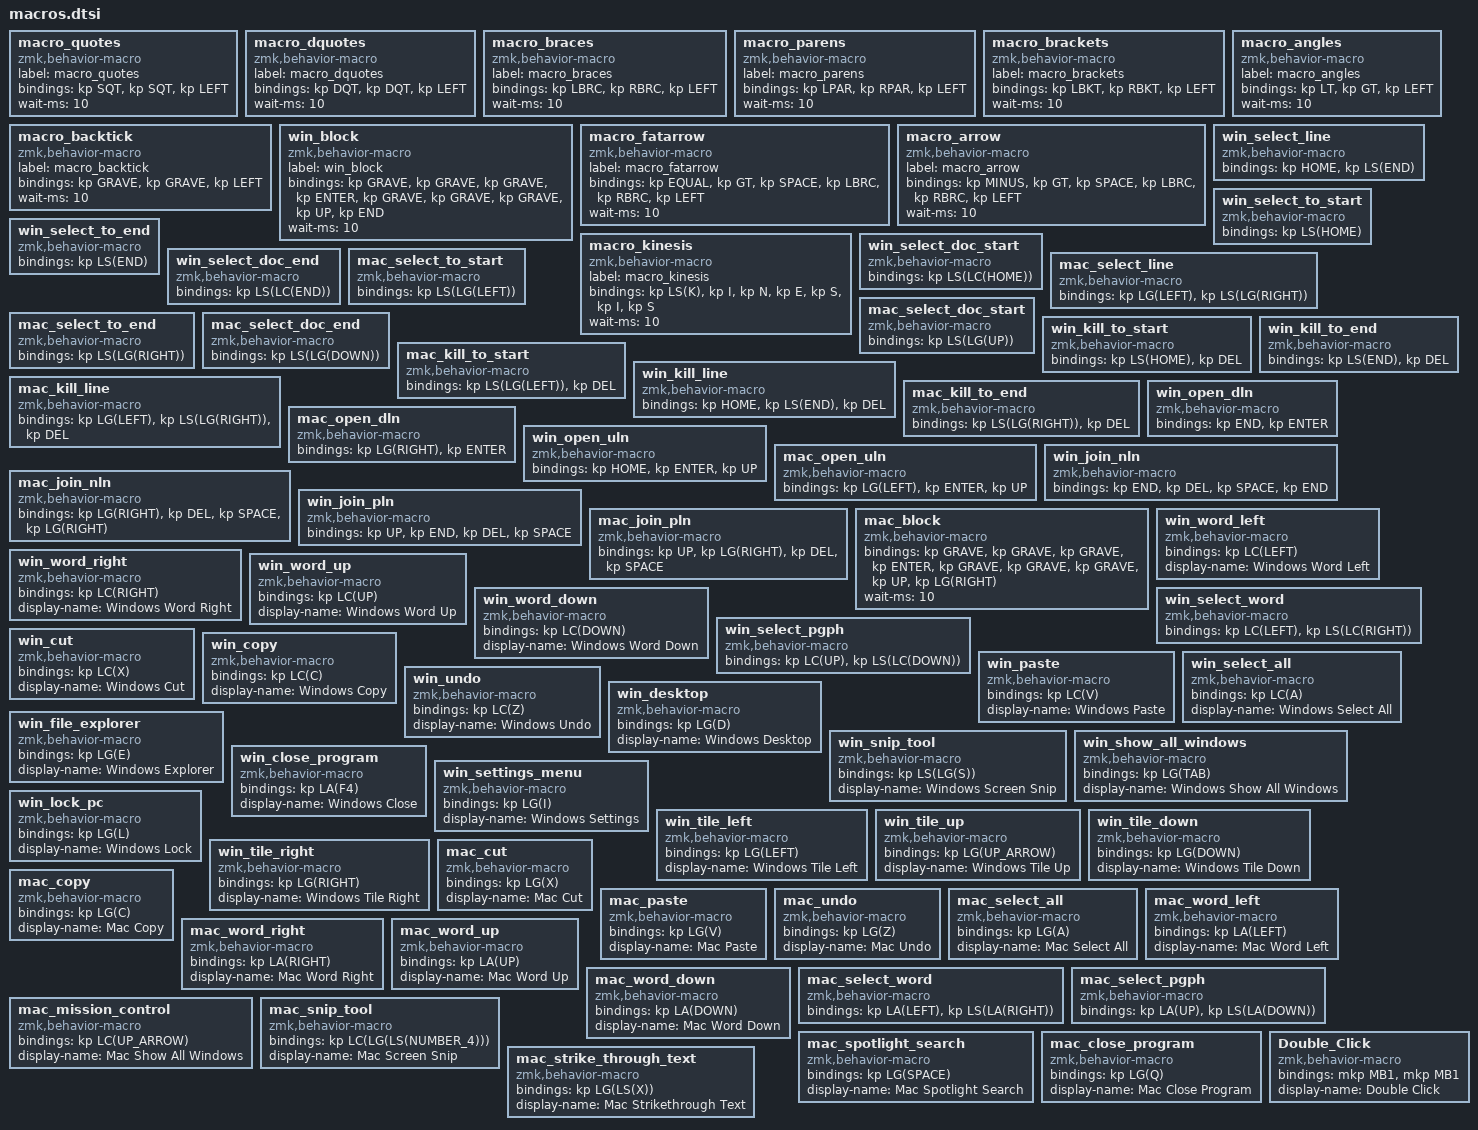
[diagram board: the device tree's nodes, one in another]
macro_quotes: macro_quotes {
    compatible = "zmk,behavior-macro";
    label = "macro_quotes";
    #binding-cells = <0>;
    bindings = <&kp SQT>, <&kp SQT>, <&kp LEFT>;
    wait-ms = <10>;
};
macro_dquotes: macro_dquotes {
    compatible = "zmk,behavior-macro";
    label = "macro_dquotes";
    #binding-cells = <0>;
    bindings = <&kp DQT>, <&kp DQT>, <&kp LEFT>;
    wait-ms = <10>;
};
macro_braces: macro_braces {
    compatible = "zmk,behavior-macro";
    label = "macro_braces";
    #binding-cells = <0>;
    bindings = <&kp LBRC>, <&kp RBRC>, <&kp LEFT>;
    wait-ms = <10>;
};
macro_parens: macro_parens {
    compatible = "zmk,behavior-macro";
    label = "macro_parens";
    #binding-cells = <0>;
    bindings = <&kp LPAR>, <&kp RPAR>, <&kp LEFT>;
    wait-ms = <10>;
};
macro_brackets: macro_brackets {
    compatible = "zmk,behavior-macro";
    label = "macro_brackets";
    #binding-cells = <0>;
    bindings = <&kp LBKT>, <&kp RBKT>, <&kp LEFT>;
    wait-ms = <10>;
};
macro_angles: macro_angles {
    compatible = "zmk,behavior-macro";
    label = "macro_angles";
    #binding-cells = <0>;
    bindings = <&kp LT>, <&kp GT>, <&kp LEFT>;
    wait-ms = <10>;
};
macro_backtick: macro_backtick {
    compatible = "zmk,behavior-macro";
    label = "macro_backtick";
    #binding-cells = <0>;
    bindings = <&kp GRAVE>, <&kp GRAVE>, <&kp LEFT>;
    wait-ms = <10>;
};
win_block: win_block {
    compatible = "zmk,behavior-macro";
    label = "win_block";
    #binding-cells = <0>;
    bindings = <&kp GRAVE>, <&kp GRAVE>, <&kp GRAVE>, <&kp ENTER>, <&kp GRAVE>, <&kp GRAVE>, <&kp GRAVE>, <&kp UP>, <&kp END>;
    wait-ms = <10>;
};
macro_fatarrow: macro_fatarrow {
    compatible = "zmk,behavior-macro";
    label = "macro_fatarrow";
    #binding-cells = <0>;
    bindings = <&kp EQUAL>, <&kp GT>, <&kp SPACE>, <&kp LBRC>, <&kp RBRC>, <&kp LEFT>;
    wait-ms = <10>;
};
macro_arrow: macro_arrow {
    compatible = "zmk,behavior-macro";
    label = "macro_arrow";
    #binding-cells = <0>;
    bindings = <&kp MINUS>, <&kp GT>, <&kp SPACE>, <&kp LBRC>, <&kp RBRC>, <&kp LEFT>;
    wait-ms = <10>;
};
macro_kinesis: macro_kinesis {
    compatible = "zmk,behavior-macro";
    label = "macro_kinesis";
    #binding-cells = <0>;
    bindings = <&kp LS(K)>, <&kp I>, <&kp N>, <&kp E>, <&kp S>, <&kp I>, <&kp S>;
    wait-ms = <10>;
};
win_select_line: win_select_line {
    compatible = "zmk,behavior-macro";
    #binding-cells = <0>;
    bindings = <
        &kp HOME
        &kp LS(END)
    >;
};
win_select_to_start: win_select_to_start {
    compatible = "zmk,behavior-macro";
    #binding-cells = <0>;
    bindings = <
        &kp LS(HOME)
    >;
};
win_select_to_end: win_select_to_end {
    compatible = "zmk,behavior-macro";
    #binding-cells = <0>;
    bindings = <
        &kp LS(END)
    >;
};
win_select_doc_start: win_select_doc_start {
    compatible = "zmk,behavior-macro";
    #binding-cells = <0>;
    bindings = <
        &kp LS(LC(HOME))
    >;
};
win_select_doc_end: win_select_doc_end {
    compatible = "zmk,behavior-macro";
    #binding-cells = <0>;
    bindings = <
        &kp LS(LC(END))
    >;
};
mac_select_line: mac_select_line {
    compatible = "zmk,behavior-macro";
    #binding-cells = <0>;
    bindings = <
        &kp LG(LEFT)
        &kp LS(LG(RIGHT))
    >;
};
mac_select_to_start: mac_select_to_start {
    compatible = "zmk,behavior-macro";
    #binding-cells = <0>;
    bindings = <
        &kp LS(LG(LEFT))
    >;
};
mac_select_to_end: mac_select_to_end {
    compatible = "zmk,behavior-macro";
    #binding-cells = <0>;
    bindings = <
        &kp LS(LG(RIGHT))
    >;
};
mac_select_doc_start: mac_select_doc_start {
    compatible = "zmk,behavior-macro";
    #binding-cells = <0>;
    bindings = <
        &kp LS(LG(UP))
    >;
};
mac_select_doc_end: mac_select_doc_end {
    compatible = "zmk,behavior-macro";
    #binding-cells = <0>;
    bindings = <
        &kp LS(LG(DOWN))
    >;
};
win_kill_to_start: win_kill_to_start {
    compatible = "zmk,behavior-macro";
    #binding-cells = <0>;
    bindings = <
        &kp LS(HOME)
        &kp DEL
    >;
};
mac_kill_to_start: mac_kill_to_start {
    compatible = "zmk,behavior-macro";
    #binding-cells = <0>;
    bindings = <
        &kp LS(LG(LEFT))
        &kp DEL
    >;
};
win_kill_line: win_kill_line {
    compatible = "zmk,behavior-macro";
    #binding-cells = <0>;
    bindings = <
        &kp HOME
        &kp LS(END)
        &kp DEL
    >;
};
mac_kill_line: mac_kill_line {
    compatible = "zmk,behavior-macro";
    #binding-cells = <0>;
    bindings = <
        &kp LG(LEFT)
        &kp LS(LG(RIGHT))
        &kp DEL
    >;
};
win_kill_to_end: win_kill_to_end {
    compatible = "zmk,behavior-macro";
    #binding-cells = <0>;
    bindings = <
        &kp LS(END)
        &kp DEL
    >;
};
mac_kill_to_end: mac_kill_to_end {
    compatible = "zmk,behavior-macro";
    #binding-cells = <0>;
    bindings = <
        &kp LS(LG(RIGHT))
        &kp DEL
    >;
};
win_open_dln: win_open_dln {
    compatible = "zmk,behavior-macro";
    #binding-cells = <0>;
    bindings = <
        &kp END
        &kp ENTER
    >;
};
mac_open_dln: mac_open_dln {
    compatible = "zmk,behavior-macro";
    #binding-cells = <0>;
    bindings = <
        &kp LG(RIGHT)
        &kp ENTER
    >;
};
win_open_uln: win_open_uln {
    compatible = "zmk,behavior-macro";
    #binding-cells = <0>;
    bindings = <
        &kp HOME
        &kp ENTER
        &kp UP
    >;
};
mac_open_uln: mac_open_uln {
    compatible = "zmk,behavior-macro";
    #binding-cells = <0>;
    bindings = <
        &kp LG(LEFT)
        &kp ENTER
        &kp UP
    >;
};
win_join_nln: win_join_nln {
    compatible = "zmk,behavior-macro";
    #binding-cells = <0>;
    bindings = <
        &kp END
        &kp DEL
        &kp SPACE
        &kp END
    >;
};
mac_join_nln: mac_join_nln {
    compatible = "zmk,behavior-macro";
    #binding-cells = <0>;
    bindings = <
        &kp LG(RIGHT)
        &kp DEL
        &kp SPACE
        &kp LG(RIGHT)
    >;
};
win_join_pln: win_join_pln {
    compatible = "zmk,behavior-macro";
    #binding-cells = <0>;
    bindings = <
        &kp UP
        &kp END
        &kp DEL
        &kp SPACE
    >;
};
mac_join_pln: mac_join_pln {
    compatible = "zmk,behavior-macro";
    #binding-cells = <0>;
    bindings = <
        &kp UP
        &kp LG(RIGHT)
        &kp DEL
        &kp SPACE
    >;
};
mac_block: mac_block {
    compatible = "zmk,behavior-macro";
    #binding-cells = <0>;
    bindings = <&kp GRAVE>, <&kp GRAVE>, <&kp GRAVE>, <&kp ENTER>, <&kp GRAVE>, <&kp GRAVE>, <&kp GRAVE>, <&kp UP>, <&kp LG(RIGHT)>;
    wait-ms = <10>;
};
win_word_left: win_word_left {
    compatible = "zmk,behavior-macro";
    #binding-cells = <0>;
    bindings = <&kp LC(LEFT)>;
    display-name = "Windows Word Left";
};
win_word_right: win_word_right {
    compatible = "zmk,behavior-macro";
    #binding-cells = <0>;
    bindings = <&kp LC(RIGHT)>;
    display-name = "Windows Word Right";
};
win_word_up: win_word_up {
    compatible = "zmk,behavior-macro";
    #binding-cells = <0>;
    bindings = <&kp LC(UP)>;
    display-name = "Windows Word Up";
};
win_word_down: win_word_down {
    compatible = "zmk,behavior-macro";
    #binding-cells = <0>;
    bindings = <&kp LC(DOWN)>;
    display-name = "Windows Word Down";
};
win_select_word: win_select_word {
    compatible = "zmk,behavior-macro";
    #binding-cells = <0>;
    bindings = <
        &kp LC(LEFT)
        &kp LS(LC(RIGHT))
    >;
};
win_select_pgph: win_select_pgph {
    compatible = "zmk,behavior-macro";
    #binding-cells = <0>;
    bindings = <
        &kp LC(UP)
        &kp LS(LC(DOWN))
    >;
};
win_cut: win_cut {
    compatible = "zmk,behavior-macro";
    #binding-cells = <0>;
    bindings = <&kp LC(X)>;
    display-name = "Windows Cut";
};
win_copy: win_copy {
    compatible = "zmk,behavior-macro";
    #binding-cells = <0>;
    bindings = <&kp LC(C)>;
    display-name = "Windows Copy";
};
win_paste: win_paste {
    compatible = "zmk,behavior-macro";
    #binding-cells = <0>;
    bindings = <&kp LC(V)>;
    display-name = "Windows Paste";
};
win_select_all: win_select_all {
    compatible = "zmk,behavior-macro";
    #binding-cells = <0>;
    bindings = <&kp LC(A)>;
    display-name = "Windows Select All";
};
win_undo: win_undo {
    compatible = "zmk,behavior-macro";
    #binding-cells = <0>;
    bindings = <&kp LC(Z)>;
    display-name = "Windows Undo";
};
win_desktop: win_desktop {
    compatible = "zmk,behavior-macro";
    #binding-cells = <0>;
    bindings = <&kp LG(D)>;
    display-name = "Windows Desktop";
};
win_file_explorer: win_file_explorer {
    compatible = "zmk,behavior-macro";
    #binding-cells = <0>;
    bindings = <&kp LG(E)>;
    display-name = "Windows Explorer";
};
win_snip_tool: win_snip_tool {
    compatible = "zmk,behavior-macro";
    #binding-cells = <0>;
    bindings = <&kp LS(LG(S))>;
    display-name = "Windows Screen Snip";
};
win_show_all_windows: win_show_all_windows {
    compatible = "zmk,behavior-macro";
    #binding-cells = <0>;
    bindings = <&kp LG(TAB)>;
    display-name = "Windows Show All Windows";
};
win_close_program: win_close_program {
    compatible = "zmk,behavior-macro";
    #binding-cells = <0>;
    bindings = <&kp LA(F4)>;
    display-name = "Windows Close";
};
win_settings_menu: win_settings_menu {
    compatible = "zmk,behavior-macro";
    #binding-cells = <0>;
    bindings = <&kp LG(I)>;
    display-name = "Windows Settings";
};
win_lock_pc: win_lock_pc {
    compatible = "zmk,behavior-macro";
    #binding-cells = <0>;
    bindings = <&kp LG(L)>;
    display-name = "Windows Lock";
};
win_tile_left: win_tile_left {
    compatible = "zmk,behavior-macro";
    #binding-cells = <0>;
    bindings = <&kp LG(LEFT)>;
    display-name = "Windows Tile Left";
};
win_tile_up: win_tile_up {
    compatible = "zmk,behavior-macro";
    #binding-cells = <0>;
    bindings = <&kp LG(UP_ARROW)>;
    display-name = "Windows Tile Up";
};
win_tile_down: win_tile_down {
    compatible = "zmk,behavior-macro";
    #binding-cells = <0>;
    bindings = <&kp LG(DOWN)>;
    display-name = "Windows Tile Down";
};
win_tile_right: win_tile_right {
    compatible = "zmk,behavior-macro";
    #binding-cells = <0>;
    bindings = <&kp LG(RIGHT)>;
    display-name = "Windows Tile Right";
};
mac_cut: mac_cut {
    compatible = "zmk,behavior-macro";
    #binding-cells = <0>;
    bindings = <&kp LG(X)>;
    display-name = "Mac Cut";
};
mac_copy: mac_copy {
    compatible = "zmk,behavior-macro";
    #binding-cells = <0>;
    bindings = <&kp LG(C)>;
    display-name = "Mac Copy";
};
mac_paste: mac_paste {
    compatible = "zmk,behavior-macro";
    #binding-cells = <0>;
    bindings = <&kp LG(V)>;
    display-name = "Mac Paste";
};
mac_undo: mac_undo {
    compatible = "zmk,behavior-macro";
    #binding-cells = <0>;
    bindings = <&kp LG(Z)>;
    display-name = "Mac Undo";
};
mac_select_all: mac_select_all {
    compatible = "zmk,behavior-macro";
    #binding-cells = <0>;
    bindings = <&kp LG(A)>;
    display-name = "Mac Select All";
};
mac_word_left: mac_word_left {
    compatible = "zmk,behavior-macro";
    #binding-cells = <0>;
    bindings = <&kp LA(LEFT)>;
    display-name = "Mac Word Left";
};
mac_word_right: mac_word_right {
    compatible = "zmk,behavior-macro";
    #binding-cells = <0>;
    bindings = <&kp LA(RIGHT)>;
    display-name = "Mac Word Right";
};
mac_word_up: mac_word_up {
    compatible = "zmk,behavior-macro";
    #binding-cells = <0>;
    bindings = <&kp LA(UP)>;
    display-name = "Mac Word Up";
};
mac_word_down: mac_word_down {
    compatible = "zmk,behavior-macro";
    #binding-cells = <0>;
    bindings = <&kp LA(DOWN)>;
    display-name = "Mac Word Down";
};
mac_select_word: mac_select_word {
    compatible = "zmk,behavior-macro";
    #binding-cells = <0>;
    bindings = <
        &kp LA(LEFT)
        &kp LS(LA(RIGHT))
    >;
};
mac_select_pgph: mac_select_pgph {
    compatible = "zmk,behavior-macro";
    #binding-cells = <0>;
    bindings = <
        &kp LA(UP)
        &kp LS(LA(DOWN))
    >;
};
mac_mission_control: mac_mission_control {
    compatible = "zmk,behavior-macro";
    #binding-cells = <0>;
    bindings = <&kp LC(UP_ARROW)>;
    display-name = "Mac Show All Windows";
};
mac_snip_tool: mac_snip_tool {
    compatible = "zmk,behavior-macro";
    #binding-cells = <0>;
    bindings = <&kp LC(LG(LS(NUMBER_4)))>;
    display-name = "Mac Screen Snip";
};
mac_spotlight_search: mac_spotlight_search {
    compatible = "zmk,behavior-macro";
    #binding-cells = <0>;
    bindings = <&kp LG(SPACE)>;
    display-name = "Mac Spotlight Search";
};
mac_close_program: mac_close_program {
    compatible = "zmk,behavior-macro";
    #binding-cells = <0>;
    bindings = <&kp LG(Q)>;
    display-name = "Mac Close Program";
};
mac_strike_through_text: mac_strike_through_text {
    compatible = "zmk,behavior-macro";
    #binding-cells = <0>;
    bindings = <&kp LG(LS(X))>;
    display-name = "Mac Strikethrough Text";
};
Double_Click: Double_Click {
    compatible = "zmk,behavior-macro";
    #binding-cells = <0>;
    bindings = <&mkp MB1 &mkp MB1>;
    display-name = "Double Click";
};
